# BL702 register map
Vendor: Bouffalo Lab; Series: WiFi BT; File version: 1.0
Registers are 32-bit, read-write, reset 0x0 unless marked. A register's access mark holds for its fields unless they carry their own. Offsets are from the block's base; [hi:lo] are bit positions; {n}, {i} and the like mark numbered series.

## ef_data_1
Base 0x40007000
{0x20+0x10*i} reg_key_slot_{i}_w0 (i=6..11)
{0x24+0x10*i} reg_key_slot_{i}_w1 (i=6..11)
{0x28+0x10*i} reg_key_slot_{i}_w2 (i=6..11)
{0x2C+0x10*i} reg_key_slot_{i}_w3 (i=6..11)
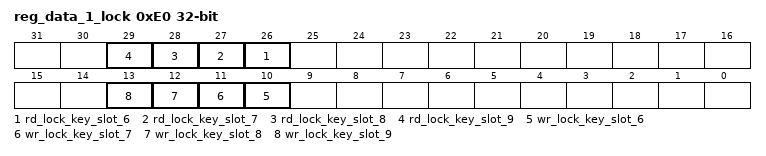
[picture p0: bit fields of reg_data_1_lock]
0xE0 reg_data_1_lock
  [n+20] rd_lock_key_slot_{n} (n=6..9), [n+4] wr_lock_key_slot_{n} (n=6..9)

## ef_ctrl — eFuse memory control
Base 0x40007000
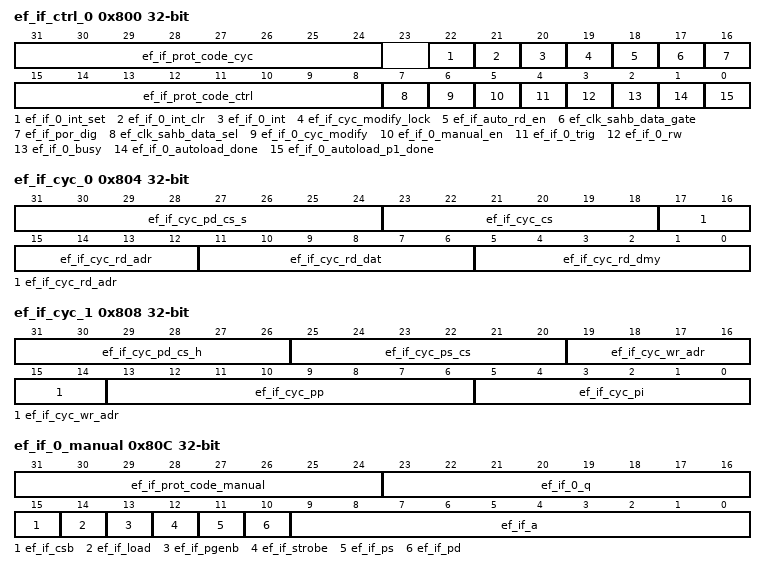
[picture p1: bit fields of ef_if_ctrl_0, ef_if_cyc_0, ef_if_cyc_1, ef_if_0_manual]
0x800 ef_if_ctrl_0
  [31:24] ef_if_prot_code_cyc, [22] ef_if_0_int_set, [21] ef_if_0_int_clr, [20] ef_if_0_int, [19] ef_if_cyc_modify_lock, [18] ef_if_auto_rd_en, [17] ef_clk_sahb_data_gate, [16] ef_if_por_dig, [15:8] ef_if_prot_code_ctrl, [7] ef_clk_sahb_data_sel, [6] ef_if_0_cyc_modify, [5] ef_if_0_manual_en, [4] ef_if_0_trig, [3] ef_if_0_rw, [2] ef_if_0_busy, [1] ef_if_0_autoload_done, [0] ef_if_0_autoload_p1_done
0x804 ef_if_cyc_0
  [31:24] ef_if_cyc_pd_cs_s, [23:18] ef_if_cyc_cs, [17:12] ef_if_cyc_rd_adr, [11:6] ef_if_cyc_rd_dat, [5:0] ef_if_cyc_rd_dmy
0x808 ef_if_cyc_1
  [31:26] ef_if_cyc_pd_cs_h, [25:20] ef_if_cyc_ps_cs, [19:14] ef_if_cyc_wr_adr, [13:6] ef_if_cyc_pp, [5:0] ef_if_cyc_pi
0x80C ef_if_0_manual
  [31:24] ef_if_prot_code_manual, [23:16] ef_if_0_q, [15] ef_if_csb, [14] ef_if_load, [13] ef_if_pgenb, [12] ef_if_strobe, [11] ef_if_ps, [10] ef_if_pd, [9:0] ef_if_a
0x810 ef_if_0_status
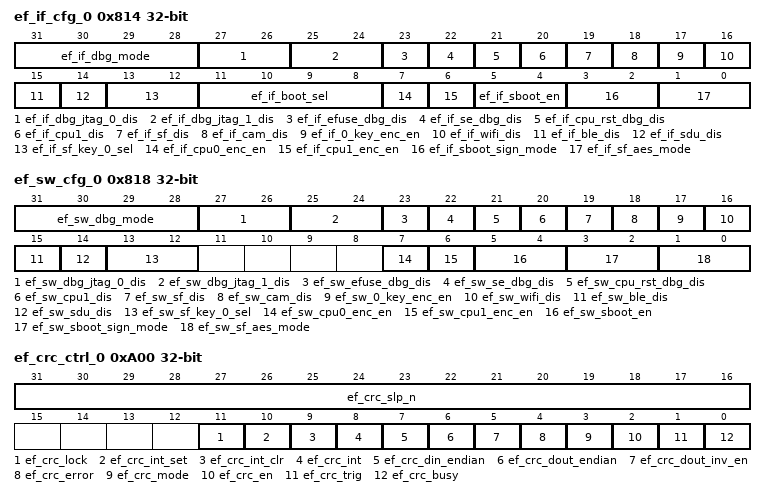
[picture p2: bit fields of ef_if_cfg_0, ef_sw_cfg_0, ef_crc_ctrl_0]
0x814 ef_if_cfg_0
  [31:28] ef_if_dbg_mode, [27:26] ef_if_dbg_jtag_0_dis, [25:24] ef_if_dbg_jtag_1_dis, [23] ef_if_efuse_dbg_dis, [22] ef_if_se_dbg_dis, [21] ef_if_cpu_rst_dbg_dis, [20] ef_if_cpu1_dis, [19] ef_if_sf_dis, [18] ef_if_cam_dis, [17] ef_if_0_key_enc_en, [16] ef_if_wifi_dis, [15] ef_if_ble_dis, [14] ef_if_sdu_dis, [13:12] ef_if_sf_key_0_sel, [11:8] ef_if_boot_sel, [7] ef_if_cpu0_enc_en, [6] ef_if_cpu1_enc_en, [5:4] ef_if_sboot_en, [3:2] ef_if_sboot_sign_mode, [1:0] ef_if_sf_aes_mode
0x818 ef_sw_cfg_0
  [31:28] ef_sw_dbg_mode, [27:26] ef_sw_dbg_jtag_0_dis, [25:24] ef_sw_dbg_jtag_1_dis, [23] ef_sw_efuse_dbg_dis, [22] ef_sw_se_dbg_dis, [21] ef_sw_cpu_rst_dbg_dis, [20] ef_sw_cpu1_dis, [19] ef_sw_sf_dis, [18] ef_sw_cam_dis, [17] ef_sw_0_key_enc_en, [16] ef_sw_wifi_dis, [15] ef_sw_ble_dis, [14] ef_sw_sdu_dis, [13:12] ef_sw_sf_key_0_sel, [7] ef_sw_cpu0_enc_en, [6] ef_sw_cpu1_enc_en, [5:4] ef_sw_sboot_en, [3:2] ef_sw_sboot_sign_mode, [1:0] ef_sw_sf_aes_mode
0x81C ef_reserved
0x820 ef_if_ana_trim_0
0x824 ef_if_sw_usage_0
0xA00 ef_crc_ctrl_0
  [31:16] ef_crc_slp_n, [11] ef_crc_lock, [10] ef_crc_int_set, [9] ef_crc_int_clr, [8] ef_crc_int, [7] ef_crc_din_endian, [6] ef_crc_dout_endian, [5] ef_crc_dout_inv_en, [4] ef_crc_error, [3] ef_crc_mode, [2] ef_crc_en, [1] ef_crc_trig, [0] ef_crc_busy
0xA04 ef_crc_ctrl_1
  [31:0] ef_crc_data_0_en
0xA08 ef_crc_ctrl_2
  [31:0] ef_crc_data_1_en
0xA0C ef_crc_ctrl_3
  [31:0] ef_crc_iv
0xA10 ef_crc_ctrl_4
  [31:0] ef_crc_golden
0xA14 ef_crc_ctrl_5
  [31:0] ef_crc_dout

## cci
Base 0x40008000
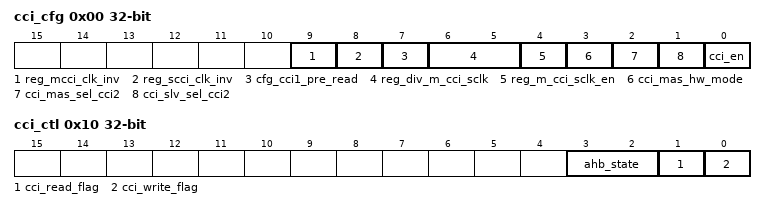
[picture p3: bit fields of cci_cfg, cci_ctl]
0x00 cci_cfg
  [9] reg_mcci_clk_inv, [8] reg_scci_clk_inv, [7] cfg_cci1_pre_read, [6:5] reg_div_m_cci_sclk, [4] reg_m_cci_sclk_en, [3] cci_mas_hw_mode, [2] cci_mas_sel_cci2, [1] cci_slv_sel_cci2, [0] cci_en
0x04 cci_addr
  [31:0] apb_cci_addr
0x08 cci_wdata
  [31:0] apb_cci_wdata
0x0C cci_rdata
  [31:0] apb_cci_rdata
0x10 cci_ctl
  [3:2] ahb_state, [1] cci_read_flag, [0] cci_write_flag

## l1c — L1 Cache control
Base 0x40009000
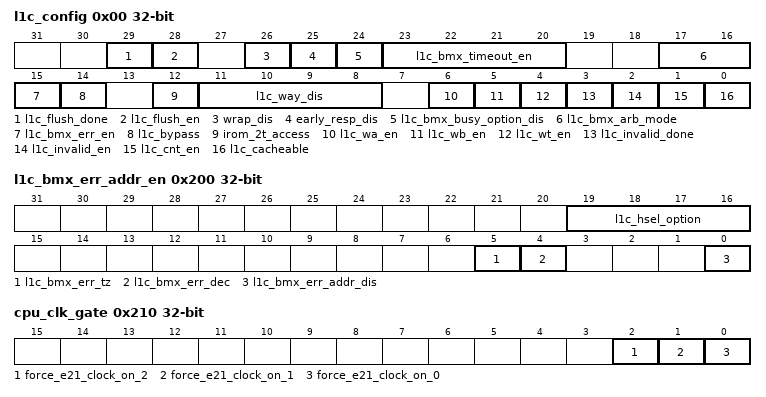
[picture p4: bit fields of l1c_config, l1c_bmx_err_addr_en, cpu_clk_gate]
0x00 l1c_config
  [29] l1c_flush_done, [28] l1c_flush_en, [26] wrap_dis, [25] early_resp_dis, [24] l1c_bmx_busy_option_dis, [23:20] l1c_bmx_timeout_en, [17:16] l1c_bmx_arb_mode, [15] l1c_bmx_err_en, [14] l1c_bypass, [12] irom_2t_access, [11:8] l1c_way_dis, [6] l1c_wa_en, [5] l1c_wb_en, [4] l1c_wt_en, [3] l1c_invalid_done, [2] l1c_invalid_en, [1] l1c_cnt_en, [0] l1c_cacheable
0x04 hit_cnt_lsb
0x08 hit_cnt_msb
0x0C miss_cnt
0x10 l1c_misc
  [30:28] l1c_fsm
0x200 l1c_bmx_err_addr_en
  [19:16] l1c_hsel_option, [5] l1c_bmx_err_tz, [4] l1c_bmx_err_dec, [0] l1c_bmx_err_addr_dis
0x204 l1c_bmx_err_addr
0x208 irom1_misr_dataout_0
0x20C irom1_misr_dataout_1
0x210 cpu_clk_gate
  [2] force_e21_clock_on_2, [1] force_e21_clock_on_1, [0] force_e21_clock_on_0
